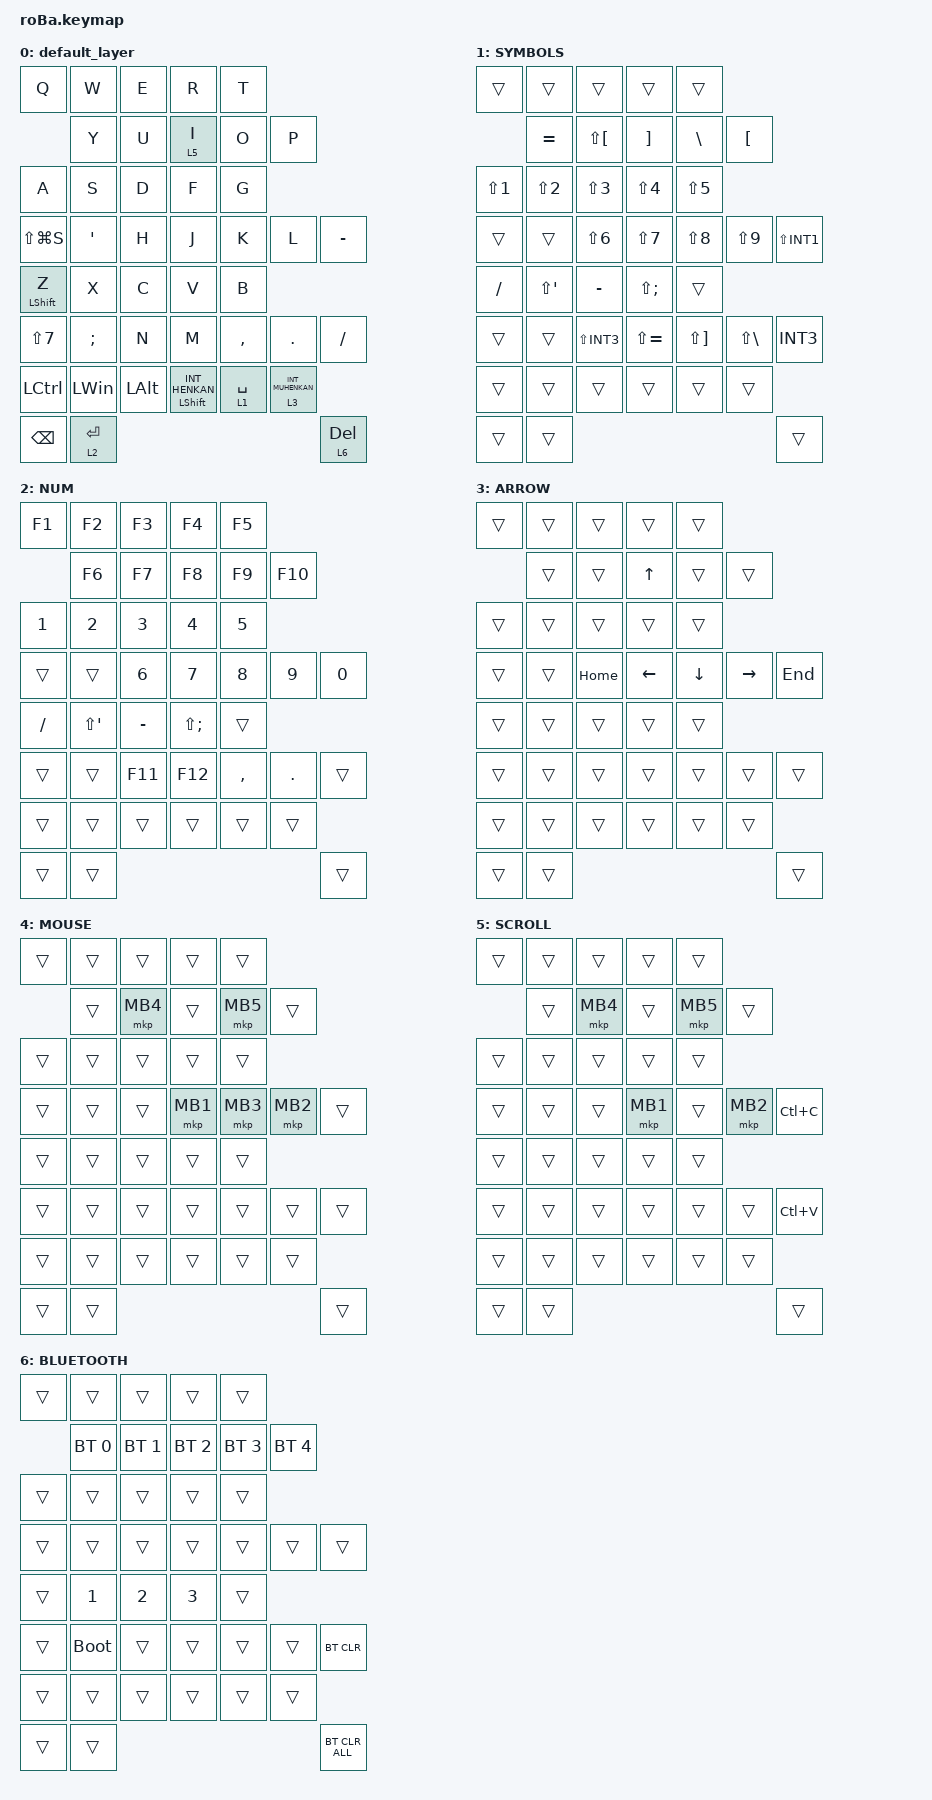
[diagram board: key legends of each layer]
#include <behaviors.dtsi>
#include <dt-bindings/zmk/bt.h>
#include <dt-bindings/zmk/keys.h>
#include <dt-bindings/zmk/pointing.h>

&mt {
    flavor = "balanced";
    quick-tap-ms = <0>;
};

&trackball {
    automouse-layer = <4>;
    scroll-layers = <5>;
    require-prior-idle-ms = <200>;
};

/ {
    combos {
        compatible = "zmk,combos";

        tab {
            bindings = <&kp TAB>;
            key-positions = <11 12>;
        };

        shift_tab {
            bindings = <&kp LS(TAB)>;
            key-positions = <12 13>;
        };

        muhennkann {
            bindings = <&to_layer_0 INT_MUHENKAN>;
            key-positions = <11 10>;
        };

        double_quotation {
            bindings = <&kp LS(N2)>;
            key-positions = <20 21>;
        };

        eq {
            bindings = <&kp LS(MINUS)>;
            key-positions = <24 25>;
        };

        escape {
            bindings = <&kp ESCAPE>;
            key-positions = <0 1>;
        };
    };

    macros {
        to_layer_0: to_layer_0 {
            compatible = "zmk,behavior-macro-one-param";
            #binding-cells = <1>;
            bindings = <&to 0 &macro_param_1to1 &kp MACRO_PLACEHOLDER>;
            label = "TO_LAYER_0";
        };
    };

    behaviors {
        lt_to_layer_0: lt_to_layer_0 {
            compatible = "zmk,behavior-hold-tap";
            label = "LAYER_TAP_TO_0";
            bindings = <&mo>, <&to_layer_0>;
            #binding-cells = <2>;
            tapping-term-ms = <200>;
        };
    };

    keymap {
        compatible = "zmk,keymap";

        default_layer {
            bindings = <
&kp Q             &kp W         &kp E         &kp R         &kp T                         
                                                              &kp Y           &kp U     &lt 5 I     &kp O      &kp P
&kp A             &kp S         &kp D         &kp F         &kp G        
&kp LS(LG(S))                                                 &kp SQT         &kp H     &kp J       &kp K      &kp L     &kp MINUS
&mt LEFT_SHIFT Z  &kp X         &kp C         &kp V         &kp B        
&kp LS(N7)                                                    &kp SEMICOLON   &kp N     &kp M       &kp COMMA  &kp DOT   &kp SLASH
&kp LCTRL         &kp LEFT_WIN  &kp LEFT_ALT  &mt LEFT_SHIFT INT_HENKAN  &lt 1 SPACE  &lt_to_layer_0 3 INT_MUHENKAN      
&kp BACKSPACE     &lt 2 ENTER                                                                       &lt 6 DEL
            >;
            sensor-bindings = <&inc_dec_kp C_AC_SCROLL_UP C_AC_SCROLL_DOWN>;
        };

        SYMBOLS {
            bindings = <
&trans     &trans       &trans       &trans         &trans                       
                                                            &kp EQUAL     &kp LS(LBKT)  &kp RBKT     &kp BSLH     &kp LBKT
&kp LS(N1) &kp LS(N2)   &kp LS(N3)   &kp LS(N4)     &kp LS(N5)  
&trans                                                      &trans        &kp LS(N6)    &kp LS(N7)   &kp LS(N8)   &kp LS(N9)   &kp LS(INT1)
&kp SLASH  &kp LS(SQT)  &kp MINUS    &kp LS(SEMI)   &trans      
&trans                                                      &trans        &kp LS(INT3)  &kp LS(EQUAL)&kp LS(RBKT) &kp LS(BSLH) &kp INT3
&trans     &trans       &trans       &trans         &trans        &trans      
&trans     &trans                                                                                                 &trans
            >;
        };

        NUM {
            bindings = <
&kp F1       &kp F2       &kp F3       &kp F4       &kp F5                       
                                                              &kp F6       &kp F7       &kp F8       &kp F9       &kp F10
&kp NUMBER_1 &kp NUMBER_2 &kp NUMBER_3 &kp NUMBER_4 &kp NUMBER_5  
&trans                                                        &trans       &kp NUMBER_6 &kp NUMBER_7 &kp NUMBER_8 &kp NUMBER_9 &kp NUMBER_0
&kp SLASH    &kp LS(SQT)  &kp MINUS    &kp LS(SEMI) &trans      
&trans                                                        &trans       &kp F11      &kp F12      &kp COMMA    &kp DOT      &trans
&trans       &trans       &trans       &trans       &trans       &trans      
&trans       &trans                                                                                               &trans
            >;
        };

        ARROW {
            bindings = <
&trans &trans &trans &trans &trans                       
                                    &trans &trans         &kp UP_ARROW           &trans         &trans
&trans &trans &trans &trans &trans  
&trans                              &trans &kp HOME &kp LEFT_ARROW &kp DOWN_ARROW   &kp RIGHT_ARROW   &kp END
&trans &trans &trans &trans &trans      
&trans                              &trans &trans         &trans           &trans         &trans       &trans
&trans &trans &trans &trans &trans &trans      
&trans &trans                                                                             &trans
            >;
            sensor-bindings = <&inc_dec_kp C_AC_SCROLL_UP C_AC_SCROLL_DOWN>;
        };

        MOUSE {
            bindings = <
&trans &trans &trans &trans &trans                       
                                    &trans &mkp MB4 &trans   &mkp MB5 &trans
&trans &trans &trans &trans &trans  
&trans                              &trans &trans   &mkp MB1 &mkp MB3 &mkp MB2 &trans
&trans &trans &trans &trans &trans      
&trans                              &trans &trans   &trans   &trans   &trans   &trans
&trans &trans &trans &trans &trans &trans      
&trans &trans                                                         &trans
            >;
        };

        SCROLL {
            bindings = <
&trans &trans &trans &trans &trans                       
                                    &trans &mkp MB4 &trans   &mkp MB5 &trans
&trans &trans &trans &trans &trans  
&trans                              &trans &trans   &mkp MB1 &trans   &mkp MB2 &kp LC(C)
&trans &trans &trans &trans &trans      
&trans                              &trans &trans   &trans   &trans   &trans   &kp LC(V)
&trans &trans &trans &trans &trans &trans      
&trans &trans                                                         &trans
            >;
        };

        BLUETOOTH {
            bindings = <
&trans       &trans       &trans       &trans       &trans                           
                                                                &bt BT_SEL 0 &bt BT_SEL 1 &bt BT_SEL 2 &bt BT_SEL 3 &bt BT_SEL 4
&trans       &trans       &trans       &trans       &trans  
&trans                                                          &trans       &trans       &trans       &trans       &trans       &trans
&trans       &kp NUMBER_1 &kp NUMBER_2 &kp NUMBER_3 &trans      
&trans                                                          &bootloader  &trans       &trans       &trans       &trans       &bt BT_CLR
&trans       &trans       &trans       &trans       &trans      &trans      
&trans       &trans                                                                                                              &bt BT_CLR_ALL
            >;
        };
    };
};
